# pktdma_rx register map
Vendor: Texas Instruments
Peripheral module from a debugger description file (folder pktdma).
Registers are 32-bit, read-write, no defined reset value unless marked. A register's access mark holds for its fields unless they carry their own. Offsets are as the file gives them; lines under a group give offsets from that group; [hi:lo] are bit positions; {n}, {i} and the like mark numbered series; 'fields as' and 'values as' point back to an identical list; <NAME> marks a mode.

## SRIO_PKTDMA_RX
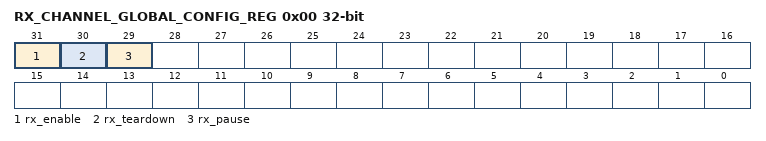
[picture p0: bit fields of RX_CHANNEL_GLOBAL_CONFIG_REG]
0x00 RX_CHANNEL_GLOBAL_CONFIG_REG — (1 of 129, stride 32)
  [31] rx_enable — Tx channel enable: 0=Channel is disabled, 1=Channel is enabled
  [30] rx_teardown — This field indicates whether or not an Rx teardown operation is complete
  [29] rx_pause — Setting this bit will request the channel to pause processing at the next packet boundary
